# SAM9X75D1GN2 register map
Vendor: Microchip Technology; Series: SAM9X7; File version: 0
Registers are 32-bit, read-write, reset 0x0 unless marked. A register's access mark holds for its fields unless they carry their own. Offsets are from the block's base; [hi:lo] are bit positions; lines under a group give offsets from that group; {n}, {i} and the like mark numbered series; 'fields as' and 'values as' point back to an identical list.

## PIT — Periodic Interval Timer
Base 0xFFFFFE40
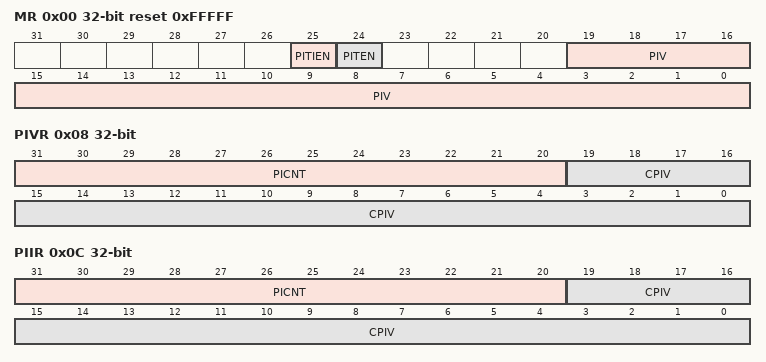
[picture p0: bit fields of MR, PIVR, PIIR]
0x00 MR reset 0xFFFFF — Mode Register
  [25] PITIEN — Periodic Interval Timer Interrupt Enable
    0=The bit PITS in PIT_SR has no effect on interrupt; 1=The bit PITS in PIT_SR asserts interrupt
  [24] PITEN — Period Interval Timer Enabled
    0=The Periodic Interval Timer is disabled when the PIV value is reached; 1=The Periodic Interval Timer is enabled
  [19:0] PIV — Periodic Interval Value
0x04 SR ro — Status Register
  [0] PITS — Periodic Interval Timer Status
    0=The Periodic Interval timer has not reached PIV since the last read of PIT_PIVR; 1=The Periodic Interval timer has reached PIV since the last read of PIT_PIVR
0x08 PIVR ro — Periodic Interval Value Register
  [31:20] PICNT — Periodic Interval Counter
  [19:0] CPIV — Current Periodic Interval Value
0x0C PIIR ro — Periodic Interval Image Register
  fields as PIVR

## PMECC — IP_Name
Base 0xFFFFE000
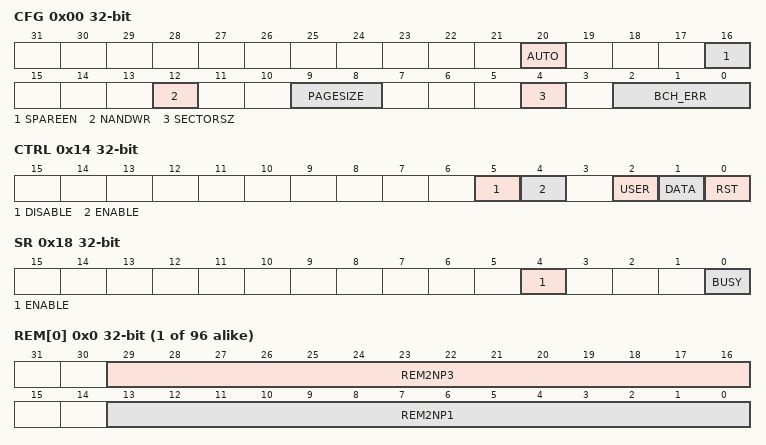
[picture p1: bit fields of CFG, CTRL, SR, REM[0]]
0x00 CFG — PMECC Configuration Register
  [20] AUTO — Automatic Mode Enable
    0=Indicates that the spare area is not protected. In that case the ECC computation takes into account the ECC area located in the spare area. (within the start address and the end address).; 1=Indicates that the spare is error protected. In this case, the ECC computation takes into account the whole spare area minus the ECC area in the ECC computation operation.
  [16] SPAREEN — Spare Enable
    0=The spare area is skipped; 1=The spare area is protected with the last sector of data
  [12] NANDWR — NAND Write Access
    0=NAND read access; 1=NAND write access
  [9:8] PAGESIZE — Number of Sectors in the Page
    0=PAGESIZE_1SEC (1 sector for main area (512 or 1024 bytes)); 1=PAGESIZE_2SEC (2 sectors for main area (1024 or 2048 bytes)); 2=PAGESIZE_4SEC (4 sectors for main area (2048 or 4096 bytes)); 3=PAGESIZE_8SEC (8 errors for main area (4096 or 8192 bytes))
  [4] SECTORSZ — Sector Size
    0=The ECC computation is based on a sector of 512 bytes; 1=The ECC computation is based on a sector of 1024 bytes
  [2:0] BCH_ERR — Error Correct Capability
    0=2 errors; 1=4 errors; 2=8 errors; 3=12 errors; 4=24 errors
0x04 SAREA — PMECC Spare Area Size Register
  [8:0] SPARESIZE — Spare Area Size
0x08 SADDR — PMECC Start Address Register
  [8:0] STARTADDR — ECC Area Start Address (byte oriented address)
0x0C EADDR — PMECC End Address Register
  [8:0] ENDADDR — ECC Area End Address (byte oriented address)
0x10 CLK — PMECC Clock Control Register
  [2:0] CLKCTRL — Clock Control Register
0x14 CTRL wo — PMECC Control Register
  [5] DISABLE — PMECC Module Disable
  [4] ENABLE — PMECC Module Enable
  [2] USER — Start a User Mode Phase
  [1] DATA — Start a Data Phase
  [0] RST — Reset the PMECC Module
0x18 SR ro — PMECC Status Register
  [4] ENABLE — PMECC Module Status
    0=The PMECC module is disabled and can be configured; 1=The PMECC module is enabled and the configuration registers cannot be written
  [0] BUSY — The Kernel of the PMECC is Busy
0x1C IER wo — PMECC Interrupt Enable register
  [0] ERRIE — Error Interrupt Enable
0x20 IDR wo — PMECC Interrupt Disable Register
  [0] ERRID — Error Interrupt Disable
0x24 IMR ro — PMECC Interrupt Mask Register
  [0] ERRIM — Error Interrupt Mask
0x28 ISR ro — PMECC Interrupt Status Register
  [7:0] ERRIS — Error Interrupt Status
{0x40+0x40*i} PMECC_ECC[{i}] (i=0..7) group
  {0x0+4j} ECC[{j}] (j=0..10) ro reset 0xFFFFFFFF — PMECC ECC x Register
    [31:0] ECC — BCH Redundancy
{0x240+0x40*i} PMECC_REM[{i}] (i=0..7) group
  {0x0+4j} REM[{j}] (j=0..11) ro — PMECC REM x Register
    [29:16] REM2NP3 — BCH Remainder 2 * N + 3
    [13:0] REM2NP1 — BCH Remainder 2 * N + 1

## PMERRLOC — Programmable Multibit ECC Error Location
Base 0xFFFFE600
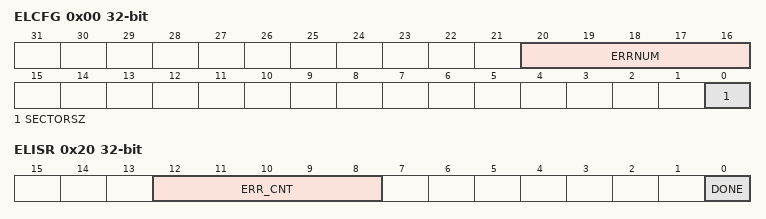
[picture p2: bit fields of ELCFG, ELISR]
0x00 ELCFG — Configuration Register
  [20:16] ERRNUM — Number of Errors
  [0] SECTORSZ — Sector Size
    0=The ECC computation is based on a 512-byte sector; 1=The ECC computation is based on a 1024-byte sector
0x04 ELPRIM ro — Primitive Register
  [15:0] PRIMITIV — Primitive Polynomial
0x08 ELEN — Enable Register
  [13:0] ENINIT — Initial Number of Bits in the Codeword
0x0C ELDIS — Disable Register
  [0] DIS — Disable Error Location Engine
0x10 ELSR — Status Register
  [0] BUSY — Error Location Engine Busy
0x14 ELIER wo — Interrupt Enable Register
  [0] DONE — Computation Terminated Interrupt Enable
0x18 ELIDR wo — Interrupt Disable Register
  [0] DONE — Computation Terminated Interrupt Disable
0x1C ELIMR ro — Interrupt Mask Register
  [0] DONE — Computation Terminated Interrupt Mask
0x20 ELISR ro — Interrupt Status Register
  [12:8] ERR_CNT — Error Counter Value
  [0] DONE — Computation Terminated Interrupt Status
0x28 SIGMA0 ro reset 0x1
  [13:0] SIGMA — Coefficient of Degree 0 in the SIGMA Polynomial
{0x28+4i} SIGMA{i} (i=1..24)
  [13:0] SIGMA — Coefficient of Degree x in the SIGMA Polynomial.
{0x8C+4i} EL[{i}] (i=0..23) ro — Error Location x Register
  [13:0] ERRLOCN — Error Position within the Set {sector area, spare area}.
